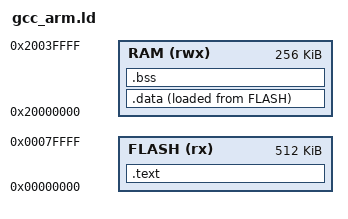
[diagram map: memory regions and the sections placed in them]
ENTRY(Reset_Handler)

MEMORY
{
    FLASH (rx) : ORIGIN = 0x00000000, LENGTH = 512K
    RAM (rwx)  : ORIGIN = 0x20000000, LENGTH = 256K
}

SECTIONS
{
    .text :
    {
        KEEP(*(.vectors))
        *(.text*)
        *(.rodata*)
        . = ALIGN(4);
        _etext = .;
    } > FLASH

    .data :
    {
        . = ALIGN(4);
        _sdata = .;
        *(.data*)
        . = ALIGN(4);
        _edata = .;
    } > RAM AT > FLASH

    _sidata = LOADADDR(.data);

    .bss (NOLOAD) :
    {
        . = ALIGN(4);
        _sbss = .;
        *(.bss*)
        *(COMMON)
        . = ALIGN(4);
        _ebss = .;
        . = ALIGN(8);
    } > RAM

    . = ALIGN(4);
    end = .;

    /* Set stack top to end of RAM, aligned to 8 bytes */
    . = ALIGN(8);
    __stack_top = ORIGIN(RAM) + LENGTH(RAM);

    /DISCARD/ :
    {
        *(.note.gnu.build-id)
        *(.ARM.exidx*)
        *(.ARM.extab*)
    }
}
